# PIC32CX1012BZ25032 register map
Vendor: Microchip Technology; Series: BZ25; File version: 0
CPU: CM4 r0p1, little endian, MPU, FPU, 3 interrupt priority bits
Registers are 32-bit, read-write, reset 0x0 unless marked. A register's access mark holds for its fields unless they carry their own. Offsets are from the block's base; [hi:lo] are bit positions; {n}, {i} and the like mark numbered series.

## PMU — PMU SPI controller
Base 0x44013E00; register names take the prefix PMU_
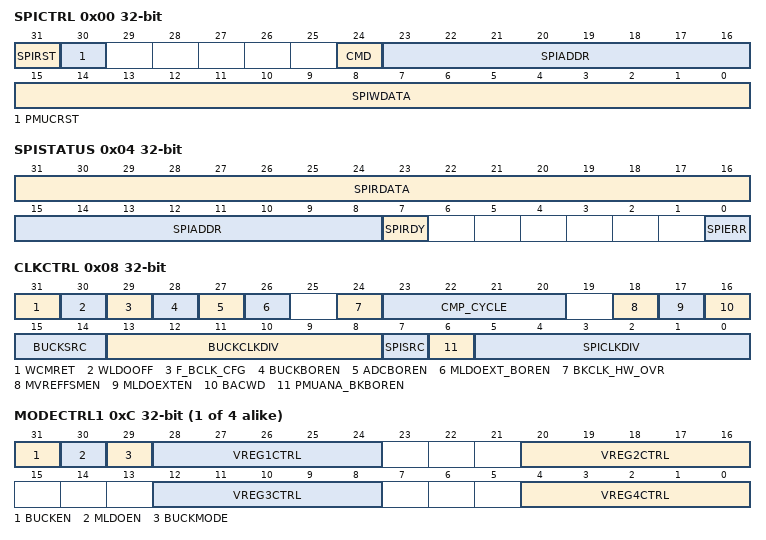
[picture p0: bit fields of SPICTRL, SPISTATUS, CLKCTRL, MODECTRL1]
0x00 SPICTRL
  [31] SPIRST, [30] PMUCRST, [24] CMD, [23:16] SPIADDR, [15:0] SPIWDATA
0x04 SPISTATUS
  [31:16] SPIRDATA, [15:8] SPIADDR, [7] SPIRDY, [0] SPIERR
0x08 CLKCTRL
  [31] WCMRET, [30] WLDOOFF, [29] F_BCLK_CFG, [28] BUCKBOREN, [27] ADCBOREN, [26] MLDOEXT_BOREN, [24] BKCLK_HW_OVR, [23:20] CMP_CYCLE, [18] MVREFFSMEN, [17] MLDOEXTEN, [16] BACWD, [15:14] BUCKSRC, [13:8] BUCKCLKDIV, [7] SPISRC, [6] PMUANA_BKBOREN, [5:0] SPICLKDIV
{0x8+4i} MODECTRL{i} (i=1..4)
  [31] BUCKEN, [30] MLDOEN, [29] BUCKMODE, [36-8n:32-8n] VREG{n}CTRL (n=1..4)
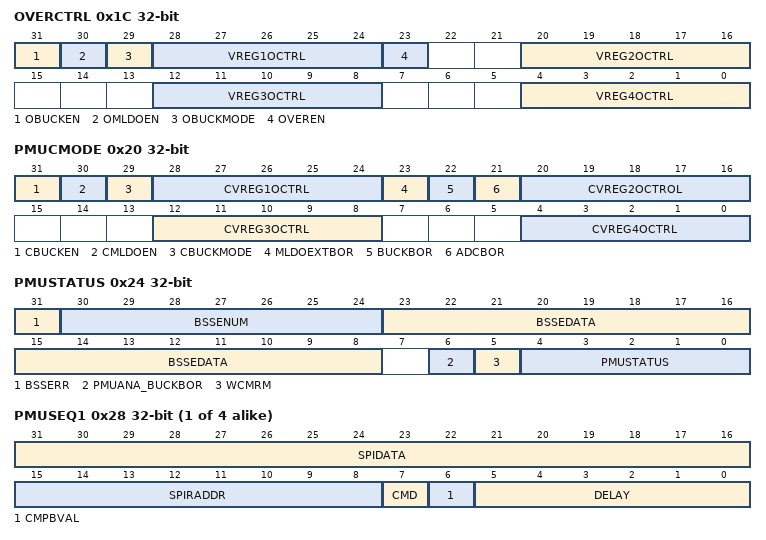
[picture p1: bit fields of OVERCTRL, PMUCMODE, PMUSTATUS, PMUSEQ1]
0x1C OVERCTRL
  [31] OBUCKEN, [30] OMLDOEN, [29] OBUCKMODE, [36-8n:32-8n] VREG{n}OCTRL (n=1..4), [23] OVEREN
0x20 PMUCMODE
  [31] CBUCKEN, [30] CMLDOEN, [29] CBUCKMODE, [28:24] CVREG1OCTRL, [23] MLDOEXTBOR, [22] BUCKBOR, [21] ADCBOR, [20:16] CVREG2OCTROL, [12:8] CVREG3OCTRL, [4:0] CVREG4OCTRL
0x24 PMUSTATUS
  [31] BSSERR, [30:24] BSSENUM, [23:8] BSSEDATA, [6] PMUANA_BUCKBOR, [5] WCMRM, [4:0] PMUSTATUS
{0x24+4i} PMUSEQ{i} (i=1..4)
  [31:16] SPIDATA, [15:8] SPIRADDR, [7] CMD, [6] CMPBVAL, [5:0] DELAY
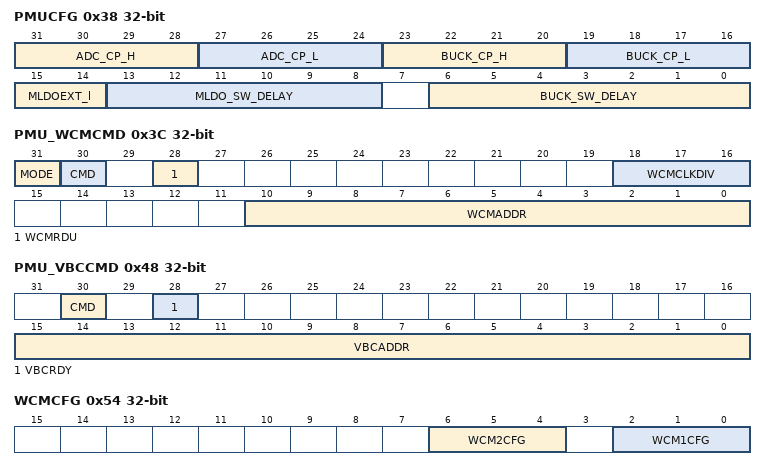
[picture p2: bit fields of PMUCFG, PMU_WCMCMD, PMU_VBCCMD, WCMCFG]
0x38 PMUCFG
  [31:28] ADC_CP_H, [27:24] ADC_CP_L, [23:20] BUCK_CP_H, [19:16] BUCK_CP_L, [15:14] MLDOEXT_l, [13:8] MLDO_SW_DELAY, [6:0] BUCK_SW_DELAY
0x3C PMU_WCMCMD
  [31] MODE, [30] CMD, [28] WCMRDU, [18:16] WCMCLKDIV, [10:0] WCMADDR
0x40 PMU_WCMWDATA
0x44 PMU_WCMRDATA
0x48 PMU_VBCCMD
  [30] CMD, [28] VBCRDY, [15:0] VBCADDR
0x4C PMU_VBCWDATA
0x50 PMU_VBCRDATA
0x54 WCMCFG
  [6:4] WCM2CFG, [2:0] WCM1CFG
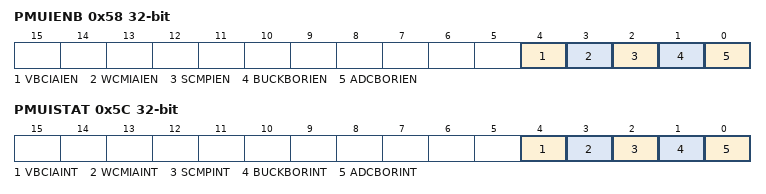
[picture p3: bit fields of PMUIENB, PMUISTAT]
0x58 PMUIENB
  [4] VBCIAIEN, [3] WCMIAIEN, [2] SCMPIEN, [1] BUCKBORIEN, [0] ADCBORIEN
0x5C PMUISTAT
  [4] VBCIAINT, [3] WCMIAINT, [2] SCMPINT, [1] BUCKBORINT, [0] ADCBORINT

## RAMECC
Base 0x41008000; register names take the prefix RAMECC_
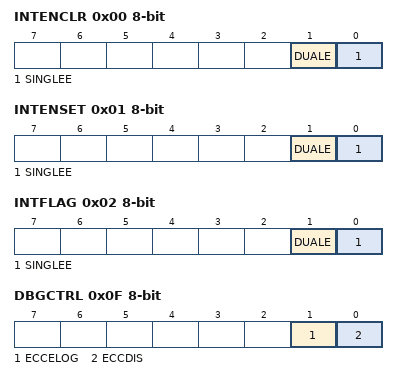
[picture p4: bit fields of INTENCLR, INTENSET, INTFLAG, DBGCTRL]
0x00 INTENCLR 8-bit — Interrupt Enable Clear
  [1] DUALE — Dual Bit ECC Error Interrupt Enable Clear
  [0] SINGLEE — Single Bit ECC Error Interrupt Enable Clear
0x01 INTENSET 8-bit — Interrupt Enable Set
  [1] DUALE — Dual Bit ECC Error Interrupt Enable Set
  [0] SINGLEE — Single Bit ECC Error Interrupt Enable Set
0x02 INTFLAG 8-bit — Interrupt Flag
  [1] DUALE — Dual Bit ECC Error Interrupt
  [0] SINGLEE — Single Bit ECC Error Interrupt
0x03 STATUS 8-bit ro
  [0] ECCDIS — ECC Disable
0x04 ERRADDR ro — Error Address
  [17:0] ERRADDR
0x0F DBGCTRL 8-bit — Debug Control
  [1] ECCELOG — ECC Error Log
  [0] ECCDIS — ECC Disable

## TRNG — True Random Generator
Base 0x42002800; register names take the prefix TRNG_
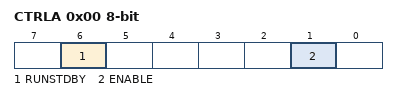
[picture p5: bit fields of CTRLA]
0x00 CTRLA 8-bit — Control A
  [6] RUNSTDBY — Run in Standby
  [1] ENABLE
0x04 EVCTRL 8-bit — Event Control
  [0] DATARDYEO — Data Ready Event Output
0x08 INTENCLR 8-bit — Interrupt Enable Clear
  [0] DATARDY — Data Ready Interrupt Enable
0x09 INTENSET 8-bit — Interrupt Enable Set
  [0] DATARDY — Data Ready Interrupt Enable
0x0A INTFLAG 8-bit — Interrupt Flag Status and Clear
  [0] DATARDY — Data Ready Interrupt Flag
0x20 DATA ro — Output Data

## WDT — Watch Dog Timer
Base 0x44000500; register names take the prefix WDT_
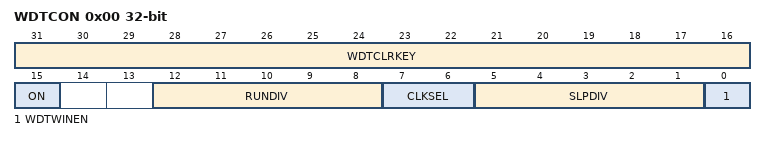
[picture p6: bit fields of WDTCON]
0x00 WDTCON — Watchdog Timer Control Register
  [31:16] WDTCLRKEY
  [15] ON — Watchdog Timer Enable bit
    1=WDTEN (The WDT module is enabled); 0=WDTOFF (The WDT module is disabled)
  [12:8] RUNDIV
  [7:6] CLKSEL
  [5:1] SLPDIV
  [0] WDTWINEN — Watchdog Timer Window Enable bit
    1=WDTWINEN (Enable windowed Watchdog Timer); 0=WDTWINDIS (Disable windowed Watchdog Timer)
0x04 WDTCONCLR
0x08 WDTCONSET
0x0C WDTCONINV

## CoreDebug
Base 0xE000EDF0; register names take the prefix CoreDebug_
0x00 DHCSR — Debug Halting Control and Status Register
  [25] S_RESET_ST ro, [24] S_RETIRE_ST ro, [19] S_LOCKUP ro, [18] S_SLEEP ro, [17] S_HALT ro, [16] S_REGRDY ro, [31:16] DBGKEY wo, [5] C_SNAPSTALL, [3] C_MASKINTS, [2] C_STEP, [1] C_HALT, [0] C_DEBUGEN
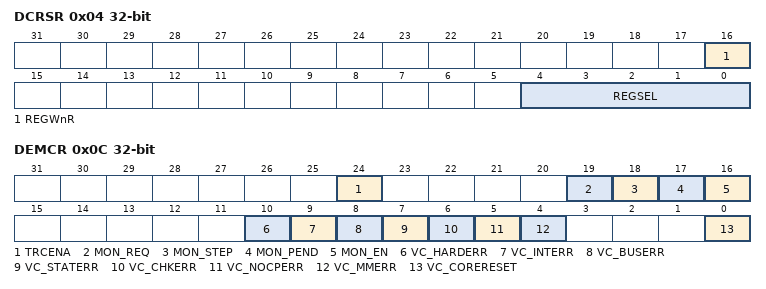
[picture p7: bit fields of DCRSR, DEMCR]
0x04 DCRSR wo — Debug Core Register Selector Register
  [16] REGWnR, [4:0] REGSEL
0x08 DCRDR — Debug Core Register Data Register
0x0C DEMCR — Debug Exception and Monitor Control Register
  [24] TRCENA, [19] MON_REQ, [18] MON_STEP, [17] MON_PEND, [16] MON_EN, [10] VC_HARDERR, [9] VC_INTERR, [8] VC_BUSERR, [7] VC_STATERR, [6] VC_CHKERR, [5] VC_NOCPERR, [4] VC_MMERR, [0] VC_CORERESET
